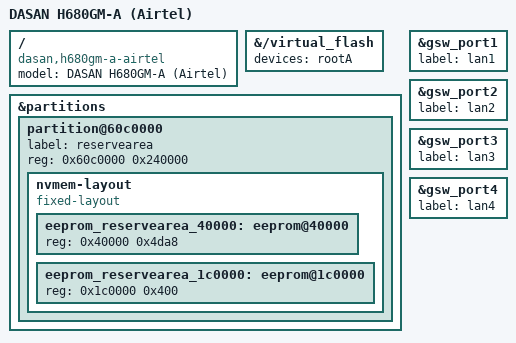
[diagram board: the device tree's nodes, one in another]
// SPDX-License-Identifier: (GPL-2.0-only OR BSD-2-Clause)
/dts-v1/;

#include "en7528_dasan_h660gm-a.dtsi"

/ {
	model = "DASAN H680GM-A (Airtel)";
	compatible = "dasan,h680gm-a-airtel", "econet,en7528";
};

/*
 * H680GM-A has a 128MB NAND (TC58CVG0S3H) vs the H660-airtel's 256MB.
 * Verified /proc/mtd layout (sizes, contiguous): bootloader@0, dzs@40000,
 * tclinux@80000(32M), tclinux_slave@2080000(32M), romfile@4080000,
 * rwfs@40c0000(32M), reservearea@60c0000(0x240000).
 * UBI rootfs = rootA(tclinux_rootfs, 28M) only; no 256MB root1.
 */
&{/virtual_flash} {
	devices = <&rootA>;
};

&partitions {
	partition@60c0000 {
		label = "reservearea";
		reg = <0x60c0000 0x240000>;
		nvmem-layout {
			compatible = "fixed-layout";
			#address-cells = <1>;
			#size-cells = <1>;

			eeprom_reservearea_40000: eeprom@40000 {
				reg = <0x40000 0x4da8>;
			};

			eeprom_reservearea_1c0000: eeprom@1c0000 {
				reg = <0x1c0000 0x400>;
			};
		};
	};
};

&gsw_port1 { label = "lan1"; };
&gsw_port2 { label = "lan2"; };
&gsw_port3 { label = "lan3"; };
&gsw_port4 { label = "lan4"; };
